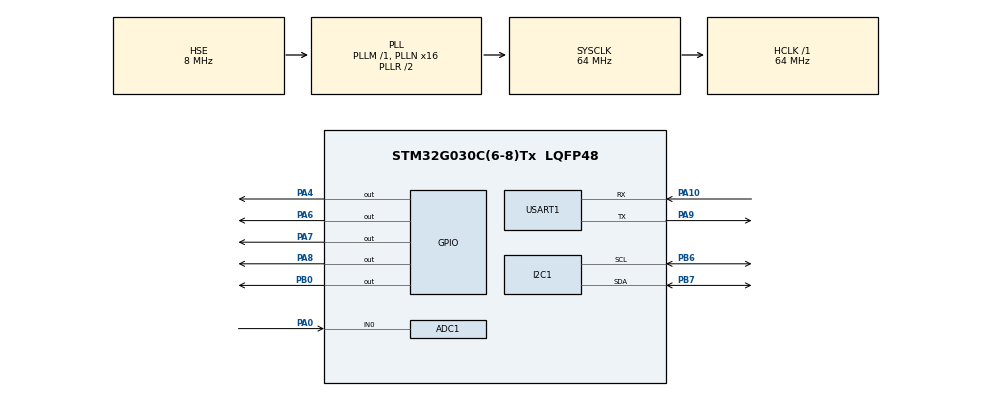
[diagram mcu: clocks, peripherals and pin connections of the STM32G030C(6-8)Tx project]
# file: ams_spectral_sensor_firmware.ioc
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ADC1.Channel-0\#ChannelRegularConversion=ADC_CHANNEL_0
ADC1.NbrOfConversionFlag=1
ADC1.Rank-0\#ChannelRegularConversion=1
ADC1.SamplingTime-0\#ChannelRegularConversion=ADC_SAMPLINGTIME_COMMON_1
ADC1.SamplingTimeCommon1=ADC_SAMPLETIME_79CYCLES_5
ADC1.SelectedChannel=ADC_CHANNEL_0
ADC1.master=1
I2C1.Timing=0x10B17DB5
Mcu.Family=STM32G0
Mcu.Name=STM32G030C(6-8)Tx
Mcu.Package=LQFP48
PA0.Mode=IN0
PA0.Signal=ADC1_IN0
PA10.Mode=Asynchronous
PA10.Signal=USART1_RX
PA13.Mode=Serial_Wire
PA13.Signal=SYS_SWDIO
PA14-BOOT0.Mode=Serial_Wire
PA14-BOOT0.Signal=SYS_SWCLK
PA4.Signal=GPIO_Output
PA6.Signal=GPIO_Output
PA7.Signal=GPIO_Output
PA8.Signal=GPIO_Output
PA9.Mode=Asynchronous
PA9.Signal=USART1_TX
PB0.Signal=GPIO_Output
PB6.Mode=I2C
PB6.Signal=I2C1_SCL
PB7.Mode=I2C
PB7.Signal=I2C1_SDA
PF0-OSC_IN\ (PF0).Mode=HSE-External-Oscillator
PF0-OSC_IN\ (PF0).Signal=RCC_OSC_IN
PF1-OSC_OUT\ (PF1).Mode=HSE-External-Oscillator
PF1-OSC_OUT\ (PF1).Signal=RCC_OSC_OUT
ProjectManager.HeapSize=0x200
ProjectManager.StackSize=0x400
ProjectManager.TargetToolchain=STM32CubeIDE
RCC.ADCFreq_Value=64000000
RCC.AHBFreq_Value=64000000
RCC.CortexFreq_Value=64000000
RCC.EXTERNAL_CLOCK_VALUE=12288000
RCC.EnbaleCSS=true
RCC.HCLKFreq_Value=64000000
RCC.HSE_VALUE=8000000
RCC.HSI_VALUE=16000000
RCC.LSE_VALUE=32768
RCC.PLLN=16
RCC.PLLSourceVirtual=RCC_PLLSOURCE_HSE
RCC.SYSCLKFreq_VALUE=64000000
RCC.SYSCLKSource=RCC_SYSCLKSOURCE_PLLCLK
RCC.VCOOutputFreq_Value=128000000
USART1.VirtualMode-Asynchronous=VM_ASYNC
board=custom

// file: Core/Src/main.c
/* USER CODE BEGIN Header */
/**
  ******************************************************************************
  * @file           : main.c
  * @brief          : Main program body
  ******************************************************************************
  * @attention
  *
  * Copyright (c) 2026 STMicroelectronics.
  * All rights reserved.
  *
  * This software is licensed under terms that can be found in the LICENSE file
  * in the root directory of this software component.
  * If no LICENSE file comes with this software, it is provided AS-IS.
  *
  ******************************************************************************
  */
/* USER CODE END Header */
#include "main.h"

/* USER CODE BEGIN Includes */
#include "spectral_app.h"
/* USER CODE END Includes */

ADC_HandleTypeDef hadc1;

I2C_HandleTypeDef hi2c1;

UART_HandleTypeDef huart1;

void SystemClock_Config(void);
static void MX_GPIO_Init(void);
static void MX_ADC1_Init(void);
static void MX_I2C1_Init(void);
static void MX_USART1_UART_Init(void);

int main(void)
{

  /* MCU Configuration--------------------------------------------------------*/

  /* Reset of all peripherals, Initializes the Flash interface and the Systick. */
  HAL_Init();

  /* Configure the system clock */
  SystemClock_Config();

  /* Initialize all configured peripherals */
  MX_GPIO_Init();
  MX_ADC1_Init();
  MX_I2C1_Init();
  MX_USART1_UART_Init();
  /* USER CODE BEGIN 2 */
  SpectralApp_Init();
  /* USER CODE END 2 */

  /* Infinite loop */
  while (1)
  {
    SpectralApp_Process();
  }
}

void SystemClock_Config(void)
{
  RCC_OscInitTypeDef RCC_OscInitStruct = {0};
  RCC_ClkInitTypeDef RCC_ClkInitStruct = {0};

  /** Configure the main internal regulator output voltage
  */
  HAL_PWREx_ControlVoltageScaling(PWR_REGULATOR_VOLTAGE_SCALE1);

  /** Initializes the RCC Oscillators according to the specified parameters
  * in the RCC_OscInitTypeDef structure.
  */
  RCC_OscInitStruct.OscillatorType = RCC_OSCILLATORTYPE_HSE;
  RCC_OscInitStruct.HSEState = RCC_HSE_ON;
  RCC_OscInitStruct.PLL.PLLState = RCC_PLL_ON;
  RCC_OscInitStruct.PLL.PLLSource = RCC_PLLSOURCE_HSE;
  RCC_OscInitStruct.PLL.PLLM = RCC_PLLM_DIV1;
  RCC_OscInitStruct.PLL.PLLN = 16;
  RCC_OscInitStruct.PLL.PLLP = RCC_PLLP_DIV2;
  RCC_OscInitStruct.PLL.PLLR = RCC_PLLR_DIV2;
  if (HAL_RCC_OscConfig(&RCC_OscInitStruct) != HAL_OK)
  {
    Error_Handler();
  }

  /** Initializes the CPU, AHB and APB buses clocks
  */
  RCC_ClkInitStruct.ClockType = RCC_CLOCKTYPE_HCLK|RCC_CLOCKTYPE_SYSCLK
                              |RCC_CLOCKTYPE_PCLK1;
  RCC_ClkInitStruct.SYSCLKSource = RCC_SYSCLKSOURCE_PLLCLK;
  RCC_ClkInitStruct.AHBCLKDivider = RCC_SYSCLK_DIV1;
  RCC_ClkInitStruct.APB1CLKDivider = RCC_HCLK_DIV1;

  if (HAL_RCC_ClockConfig(&RCC_ClkInitStruct, FLASH_LATENCY_2) != HAL_OK)
  {
    Error_Handler();
  }

  /** Enables the Clock Security System
  */
  HAL_RCC_EnableCSS();
}

static void MX_ADC1_Init(void)
{

  ADC_ChannelConfTypeDef sConfig = {0};

  /** Configure the global features of the ADC (Clock, Resolution, Data Alignment and number of conversion)
  */
  hadc1.Instance = ADC1;
  hadc1.Init.ClockPrescaler = ADC_CLOCK_SYNC_PCLK_DIV2;
  hadc1.Init.Resolution = ADC_RESOLUTION_12B;
  hadc1.Init.DataAlign = ADC_DATAALIGN_RIGHT;
  hadc1.Init.ScanConvMode = ADC_SCAN_DISABLE;
  hadc1.Init.EOCSelection = ADC_EOC_SINGLE_CONV;
  hadc1.Init.LowPowerAutoWait = DISABLE;
  hadc1.Init.LowPowerAutoPowerOff = DISABLE;
  hadc1.Init.ContinuousConvMode = DISABLE;
  hadc1.Init.NbrOfConversion = 1;
  hadc1.Init.DiscontinuousConvMode = DISABLE;
  hadc1.Init.ExternalTrigConv = ADC_SOFTWARE_START;
  hadc1.Init.ExternalTrigConvEdge = ADC_EXTERNALTRIGCONVEDGE_NONE;
  hadc1.Init.DMAContinuousRequests = DISABLE;
  hadc1.Init.Overrun = ADC_OVR_DATA_PRESERVED;
  hadc1.Init.SamplingTimeCommon1 = ADC_SAMPLETIME_79CYCLES_5;
  hadc1.Init.SamplingTimeCommon2 = ADC_SAMPLETIME_1CYCLE_5;
  hadc1.Init.OversamplingMode = DISABLE;
  hadc1.Init.TriggerFrequencyMode = ADC_TRIGGER_FREQ_HIGH;
  if (HAL_ADC_Init(&hadc1) != HAL_OK)
  {
    Error_Handler();
  }

  /** Configure Regular Channel
  */
  sConfig.Channel = ADC_CHANNEL_0;
  sConfig.Rank = ADC_REGULAR_RANK_1;
  sConfig.SamplingTime = ADC_SAMPLINGTIME_COMMON_1;
  if (HAL_ADC_ConfigChannel(&hadc1, &sConfig) != HAL_OK)
  {
    Error_Handler();
  }

}

static void MX_I2C1_Init(void)
{

  hi2c1.Instance = I2C1;
  hi2c1.Init.Timing = 0x10B17DB5;
  hi2c1.Init.OwnAddress1 = 0;
  hi2c1.Init.AddressingMode = I2C_ADDRESSINGMODE_7BIT;
  hi2c1.Init.DualAddressMode = I2C_DUALADDRESS_DISABLE;
  hi2c1.Init.OwnAddress2 = 0;
  hi2c1.Init.OwnAddress2Masks = I2C_OA2_NOMASK;
  hi2c1.Init.GeneralCallMode = I2C_GENERALCALL_DISABLE;
  hi2c1.Init.NoStretchMode = I2C_NOSTRETCH_DISABLE;
  if (HAL_I2C_Init(&hi2c1) != HAL_OK)
  {
    Error_Handler();
  }

  /** Configure Analogue filter
  */
  if (HAL_I2CEx_ConfigAnalogFilter(&hi2c1, I2C_ANALOGFILTER_ENABLE) != HAL_OK)
  {
    Error_Handler();
  }

  /** Configure Digital filter
  */
  if (HAL_I2CEx_ConfigDigitalFilter(&hi2c1, 0) != HAL_OK)
  {
    Error_Handler();
  }

}

static void MX_USART1_UART_Init(void)
{

  huart1.Instance = USART1;
  huart1.Init.BaudRate = 115200;
  huart1.Init.WordLength = UART_WORDLENGTH_8B;
  huart1.Init.StopBits = UART_STOPBITS_1;
  huart1.Init.Parity = UART_PARITY_NONE;
  huart1.Init.Mode = UART_MODE_TX_RX;
  huart1.Init.HwFlowCtl = UART_HWCONTROL_NONE;
  huart1.Init.OverSampling = UART_OVERSAMPLING_16;
  huart1.Init.OneBitSampling = UART_ONE_BIT_SAMPLE_DISABLE;
  huart1.Init.ClockPrescaler = UART_PRESCALER_DIV1;
  huart1.AdvancedInit.AdvFeatureInit = UART_ADVFEATURE_NO_INIT;
  if (HAL_UART_Init(&huart1) != HAL_OK)
  {
    Error_Handler();
  }
  if (HAL_UARTEx_SetTxFifoThreshold(&huart1, UART_TXFIFO_THRESHOLD_1_8) != HAL_OK)
  {
    Error_Handler();
  }
  if (HAL_UARTEx_SetRxFifoThreshold(&huart1, UART_RXFIFO_THRESHOLD_1_8) != HAL_OK)
  {
    Error_Handler();
  }
  if (HAL_UARTEx_DisableFifoMode(&huart1) != HAL_OK)
  {
    Error_Handler();
  }

}

static void MX_GPIO_Init(void)
{
  GPIO_InitTypeDef GPIO_InitStruct = {0};

  /* GPIO Ports Clock Enable */
  __HAL_RCC_GPIOF_CLK_ENABLE();
  __HAL_RCC_GPIOA_CLK_ENABLE();
  __HAL_RCC_GPIOB_CLK_ENABLE();

  /*Configure GPIO pin Output Level */
  HAL_GPIO_WritePin(GPIOA, GPIO_PIN_4|GPIO_PIN_6|GPIO_PIN_7|GPIO_PIN_8, GPIO_PIN_RESET);

  /*Configure GPIO pin Output Level */
  HAL_GPIO_WritePin(GPIOB, GPIO_PIN_0, GPIO_PIN_RESET);

  /*Configure GPIO pins : PA4 PA6 PA7 PA8 */
  GPIO_InitStruct.Pin = GPIO_PIN_4|GPIO_PIN_6|GPIO_PIN_7|GPIO_PIN_8;
  GPIO_InitStruct.Mode = GPIO_MODE_OUTPUT_PP;
  GPIO_InitStruct.Pull = GPIO_NOPULL;
  GPIO_InitStruct.Speed = GPIO_SPEED_FREQ_LOW;
  HAL_GPIO_Init(GPIOA, &GPIO_InitStruct);

  /*Configure GPIO pin : PB0 */
  GPIO_InitStruct.Pin = GPIO_PIN_0;
  GPIO_InitStruct.Mode = GPIO_MODE_OUTPUT_PP;
  GPIO_InitStruct.Pull = GPIO_NOPULL;
  GPIO_InitStruct.Speed = GPIO_SPEED_FREQ_LOW;
  HAL_GPIO_Init(GPIOB, &GPIO_InitStruct);

}

/* USER CODE BEGIN 4 */
void HAL_UART_RxCpltCallback(UART_HandleTypeDef *huart)
{
  SpectralApp_UartRxCpltCallback(huart);
}

void HAL_UART_ErrorCallback(UART_HandleTypeDef *huart)
{
  SpectralApp_UartErrorCallback(huart);
}
/* USER CODE END 4 */

void Error_Handler(void)
{
  __disable_irq();
  while (1)
  {
  }
}
